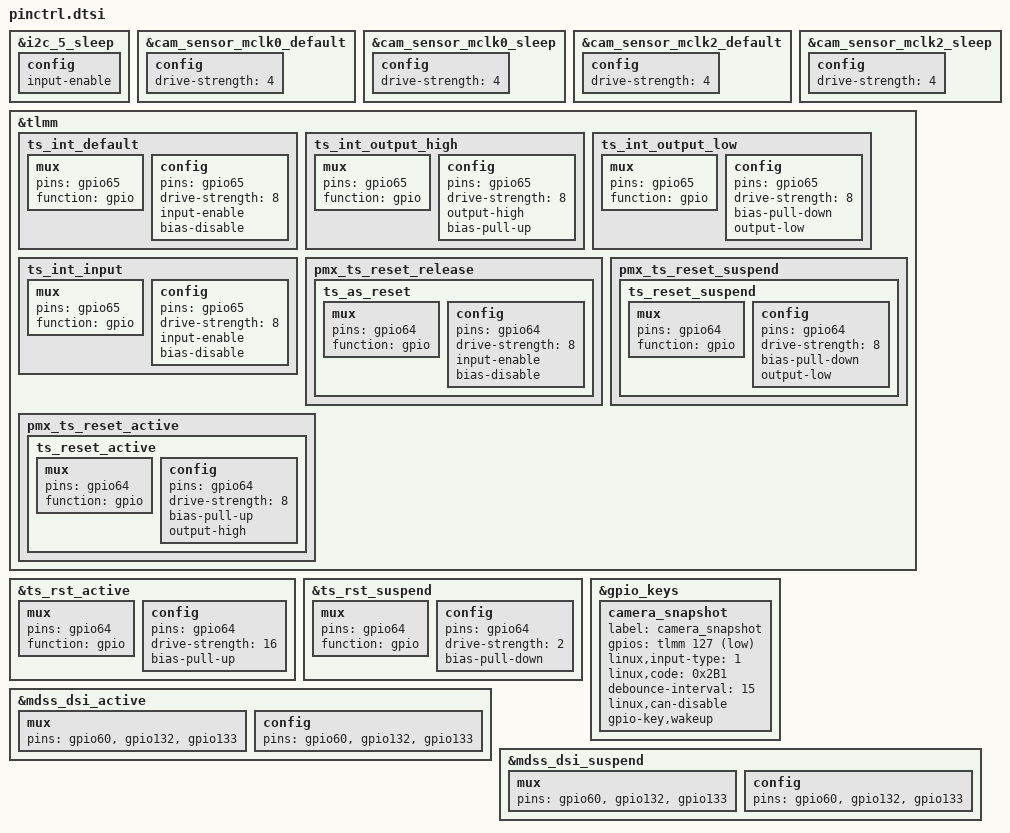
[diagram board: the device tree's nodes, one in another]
&i2c_5_sleep {
	config {
		input-enable;
	};
};

&cam_sensor_mclk0_default {
	config {
		drive-strength = <4>; /* 4 MA */
	};
};

&cam_sensor_mclk0_sleep {
	config {
		drive-strength = <4>; /* 4 MA */
	};
};

&cam_sensor_mclk2_default {
	config {
		drive-strength = <4>; /* 4 MA */
	};
};

&cam_sensor_mclk2_sleep {
	config {
		drive-strength = <4>; /* 4 MA */
	};
};

&tlmm {
	/delete-node/ fm_pin;

	ts_int_default: ts_int_default {
		mux {
			pins = "gpio65";
			function = "gpio";
		};
		config {
			pins = "gpio65";
			drive-strength = <8>;
			/*bias-pull-up;*/
			input-enable;
			bias-disable;
		};
	};

	ts_int_output_high: ts_int_output_high {
		mux {
			pins = "gpio65";
			function = "gpio";
		};
		config {
			pins = "gpio65";
			drive-strength = <8>;
			output-high;
			bias-pull-up;
		};
	};

	ts_int_output_low: ts_int_output_low {
		mux {
			pins = "gpio65";
			function = "gpio";
		};
		config {
			pins = "gpio65";
			drive-strength = <8>;
			bias-pull-down;
			output-low;
		};
	};

	ts_int_input: ts_int_input {
		mux {
			pins = "gpio65";
			function = "gpio";
		};
		config {
			pins = "gpio65";
			drive-strength = <8>;
			input-enable;
			bias-disable;
		};
	};

	pmx_ts_reset_release {
		ts_as_reset: ts_as_reset {
			mux {
				pins = "gpio64";
				function = "gpio";
			};

			config {
				pins = "gpio64";
				drive-strength = <8>;
				input-enable;
				bias-disable;
			};
		};
	};

	pmx_ts_reset_suspend {
		ts_reset_suspend: ts_reset_suspend {
			mux {
				pins = "gpio64";
				function = "gpio";
			};

			config {
				pins = "gpio64";
				drive-strength = <8>;
				bias-pull-down;
				output-low;
			};
		};
	};

	pmx_ts_reset_active {
		ts_reset_active: ts_reset_active {
			mux {
				pins = "gpio64";
				function = "gpio";
			};

			config {
				pins = "gpio64";
				drive-strength = <8>;
				bias-pull-up;
				output-high;
			};
		};
	};
};

&ts_rst_active {
	mux {
			pins = "gpio64";
			function = "gpio";
	};

	config {
			pins = "gpio64";
			drive-strength = <16>;
			bias-pull-up;
	};
};

&ts_rst_suspend {
	mux {
			pins = "gpio64";
			function = "gpio";
	};

	config {
			pins = "gpio64";
			drive-strength = <2>;
			bias-pull-down;
	};
};

&gpio_keys {
	camera_snapshot {
		label = "camera_snapshot";
		gpios = <&tlmm 127 0x1>;
		linux,input-type = <1>;
		linux,code = <0x2B1>;
		debounce-interval = <15>;
		linux,can-disable;
		gpio-key,wakeup;
	};
};

&mdss_dsi_active {
	mux {
		pins = "gpio60","gpio132","gpio133";
	};
	config {
		pins = "gpio60","gpio132","gpio133";
	};
};

&mdss_dsi_suspend {
	mux {
		pins = "gpio60","gpio132","gpio133";
	};
	config {
		pins = "gpio60","gpio132","gpio133";
	};
};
